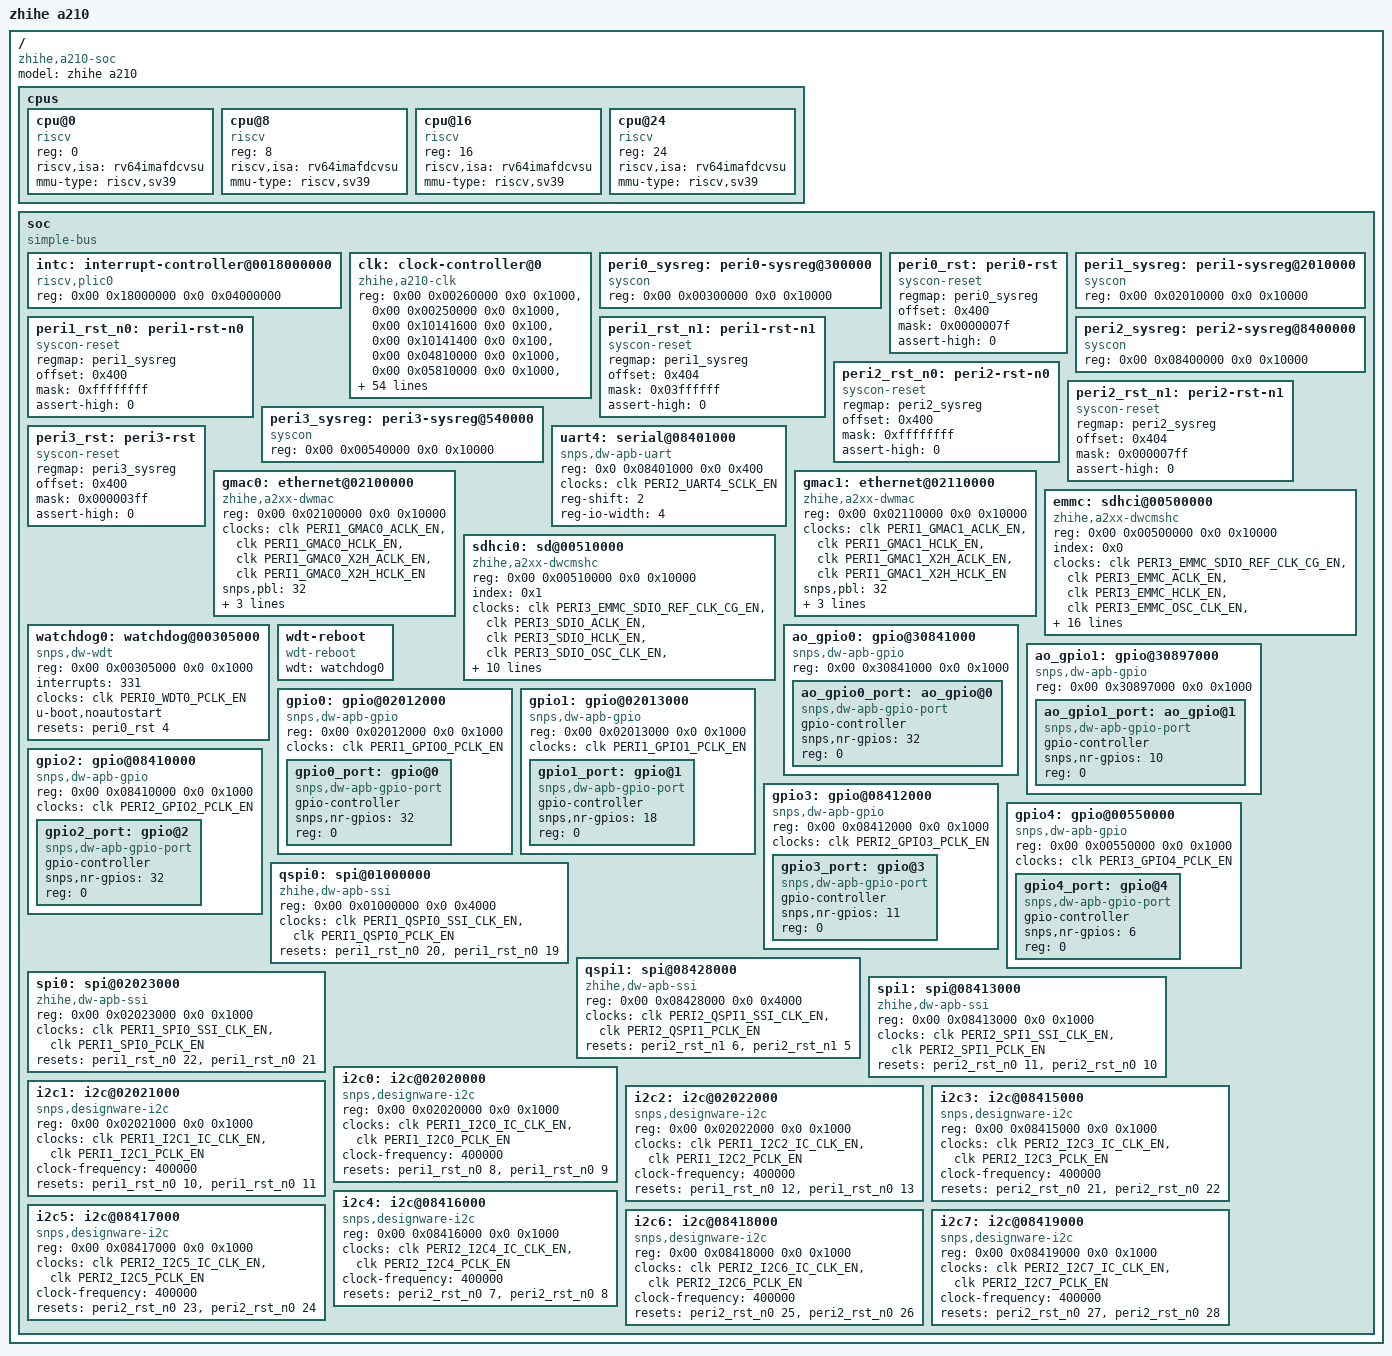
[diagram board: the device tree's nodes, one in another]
// SPDX-License-Identifier: GPL-2.0+
/*
 * (C) Copyright 2024 Zhihe Computing Technology (Shenzhen) Co., Ltd.
 */

#include <dt-bindings/clock/a210-clock.h>

/ {
	model = "zhihe a210";
	compatible = "zhihe,a210-soc";
	#address-cells = <2>;
	#size-cells = <2>;

	cpus {
		#address-cells = <1>;
		#size-cells = <0>;
		bootph-pre-ram;
		cpu@0 {
			device_type = "cpu";
			reg = <0>;
			status = "okay";
			compatible = "riscv";
			riscv,isa = "rv64imafdcvsu";
			mmu-type = "riscv,sv39";
			bootph-pre-ram;
		};

		cpu@8 {
			device_type = "cpu";
			reg = <8>;
			status = "okay";
			compatible = "riscv";
			riscv,isa = "rv64imafdcvsu";
			mmu-type = "riscv,sv39";
			bootph-pre-ram;
		};
		cpu@16 {
			device_type = "cpu";
			reg = <16>;
			status = "okay";
			compatible = "riscv";
			riscv,isa = "rv64imafdcvsu";
			mmu-type = "riscv,sv39";
			bootph-pre-ram;
		};
		cpu@24 {
			device_type = "cpu";
			reg = <24>;
			status = "okay";
			compatible = "riscv";
			riscv,isa = "rv64imafdcvsu";
			mmu-type = "riscv,sv39";
			bootph-pre-ram;
		};
	};

	soc {
		#address-cells = <2>;
		#size-cells = <2>;
		compatible = "simple-bus";
		ranges;
		bootph-pre-ram;

		intc: interrupt-controller@0018000000 {
			compatible = "riscv,plic0";
			reg = <0x00 0x18000000 0x0 0x04000000>;
			status = "okay";
		};

		clk: clock-controller@0 {
			compatible = "zhihe,a210-clk";
			reg = <0x00 0x00260000 0x0 0x1000>,<0x00 0x00250000 0x0 0x1000>,
				  <0x00 0x10141600 0x0 0x100>,<0x00 0x10141400 0x0 0x100>,
				  <0x00 0x04810000 0x0 0x1000>,<0x00 0x05810000 0x0 0x1000>,
				  <0x00 0x04900000 0x0 0x1000>,<0x00 0x20250000 0x0 0x1000>,
				  <0x00 0x10140a00 0x0 0x100>, <0x00 0x10140c00 0x0 0x100>,
				  <0x00 0x00300000 0x0 0x1000>,<0x00 0x02010000 0x0 0x1000>,
				  <0x00 0x08400000 0x0 0x1000>,<0x00 0x00540000 0x0 0x1000>;
			reg-names = "PLL_WRAP","TOP_CRG","CPU_SS_CLK_SYSREG","CPU_SS_CPU_PLL",
						"DDR0_SYSREG","DDR1_SYSREG","SLC_DUAL_SYSREG","TOP_CRG_T",
						"CPU_SS_C908_CPU_CLK_CCU","CPU_SS_C920_CPU_CLK_CCU",
						"PERI0_SYSREG", "PERI1_SYSREG", "PERI2_SYSREG", "PERI3_SYSREG";
			assigned-clocks = <&clk TOP_CFG_ACLK_DIV>, <&clk TOP_PCLK_DIV>,
							<&clk AMUX_CLK_DIV>, <&clk IOMMU_PTW_ACLK_DIV>,
							<&clk NOC_CCLK_MUX>, <&clk NOC_CCLK_DIV>,
							<&clk TOP_CPUSYS_BUS_CLK_MUX>, <&clk TOP_CPUSYS_BUS_CLK_DIV>,
							<&clk TOP_CPUSYS_PIC_CLK_MUX>, <&clk TOP_CPUSYS_PIC_CLK_DIV>,
							<&clk TOP_PERI_EMMC_REF_CLK_MUX>, <&clk TOP_PERI_EMMC_REF_CLK_DIV>,
							<&clk TOP_PERI_MST_ACLK0_DIV>, <&clk TOP_PERI_MST_CLK1_DIV>,
							<&clk TOP_PERI_HIRES_CLK0_DIV>, <&clk TOP_PERI_HIRES_CLK1_DIV>,
							<&clk TOP_PERI_SPI_SSI_CLK0_DIV>, <&clk TOP_PERI_SPI_SSI_CLK1_DIV>,
							<&clk TOP_PERI_QSPI_SSI_CLK_MUX0>, <&clk TOP_PERI_QSPI_SSI_CLK_MUX1>,
							<&clk I2C_IC_CLK>, <&clk TOP_UART_SCLK_MUX>;
			assigned-clock-rates = <330000000>, /* top_cfg_aclk */
							<165000000>, /* top_pclk */
							<660000000>, /* top_amux_clk_div */
							<330000000>, /* iommu_ptw_aclk_div */
							<0>,         /* noc_cclk_mux */
							<880000000>, /* noc_cclk_div */
							<0>,         /* top_cpusys_bus_clk_mux */
							<1000000000>,/* top_cpusys_bus_clk */
							<0>,         /* top_cpusys_pic_clk_mux */
							<1000000000>,/* top_cpusys_pic_clk */
							<0>,         /* emmc_ref_clk_mux */
							<786432000>, /* emmc_ref_clk */
							<330000000>, /* peri1_mst_aclk */
							<440000000>, /* peri3_mst_aclk */
							<80000000>,  /* peri1_hires_clk */
							<80000000>,  /* peri2_hires_clk */
							<421478400>, /* peri1_spi_ssi_clk */
							<421478400>, /* peri2_spi_ssi_clk */
							<421478400>, /* peri1_qspi_ssi_clk */
							<421478400>, /* peri2_qspi_ssi_clk */
							<100000000>, /* i2c_ic_clk */
							<100000000>;  /* uart_sclk */
			assigned-clock-parents = <&clk VIDEO_PLL_FOUT1PH0>, <0>,
							<0>, <0>,
							<&clk VIDEO_PLL_FOUTVCO>, <0>,
							<&clk VIDEO_PLL_FOUTVCO>, <0>,
							<&clk GMAC_PLL_FOUTVCO>, <0>,
							<&clk AUDIO0_PLL_FOUTVCO>, <&clk TOP_PERI_EMMC_REF_CLK_MUX>,
							<&clk VIDEO_PLL_FOUT1PH0>, <0>,
							<0>, <0>,
							<&clk AUDIO1_PLL_FOUTVCO>, <&clk AUDIO1_PLL_FOUTVCO>,
							<&clk TOP_PERI_QSPI0_SSI_CLK_DIV1>, <&clk TOP_PERI_QSPI1_SSI_CLK_DIV1>,
							<&clk GMAC_PLL_FOUTPOSTDIV>, <&clk UART_SCLK_100M>;
			#clock-cells = <1>;
			bootph-pre-ram;
			/* pll */
			audio0_pll_foutvco_frequency = <2359296000>;
			audio1_pll_foutvco_frequency = <2528870400>;
			video_pll_foutvco_frequency = <2640000000>;
			gmac_pll_foutvco_frequency = <3000000000>;
			dpu1_pll_foutvco_frequency = <2376000000>;
			dpu2_pll_foutvco_frequency = <2376000000>;
			c908_pll_foutvco_frequency = <1200000000>;
			c920_pll_foutvco_frequency = <2040000000>;

			status = "okay";
		};

		peri0_sysreg: peri0-sysreg@300000 {
			compatible = "syscon";
			reg = <0x00 0x00300000 0x0 0x10000>;
		};

		peri0_rst: peri0-rst {
			compatible = "syscon-reset";
			regmap = <&peri0_sysreg>;
			offset = <0x400>;
			mask = <0x0000007f>;
			assert-high = <0>;
			#reset-cells = <1>;
		};
	
		peri1_sysreg: peri1-sysreg@2010000 {
			compatible = "syscon";
			reg = <0x00 0x02010000 0x0 0x10000>;
		};

		peri1_rst_n0: peri1-rst-n0 {
			compatible = "syscon-reset";
			regmap = <&peri1_sysreg>;
			offset = <0x400>;
			mask = <0xffffffff>;
			assert-high = <0>;
			#reset-cells = <1>;
		};

		peri1_rst_n1: peri1-rst-n1 {
			compatible = "syscon-reset";
			regmap = <&peri1_sysreg>;
			offset = <0x404>;
			mask = <0x03ffffff>;
			assert-high = <0>;
			#reset-cells = <1>;
		};

		peri2_sysreg: peri2-sysreg@8400000 {
			compatible = "syscon";
			reg = <0x00 0x08400000 0x0 0x10000>;
		};

		peri2_rst_n0: peri2-rst-n0 {
			compatible = "syscon-reset";
			regmap = <&peri2_sysreg>;
			offset = <0x400>;
			mask = <0xffffffff>;
			assert-high = <0>;
			#reset-cells = <1>;
		};

		peri2_rst_n1: peri2-rst-n1 {
			compatible = "syscon-reset";
			regmap = <&peri2_sysreg>;
			offset = <0x404>;
			mask = <0x000007ff>;
			assert-high = <0>;
			#reset-cells = <1>;
		};

		peri3_sysreg: peri3-sysreg@540000 {
			compatible = "syscon";
			reg = <0x00 0x00540000 0x0 0x10000>;
		};

		peri3_rst: peri3-rst {
			compatible = "syscon-reset";
			regmap = <&peri3_sysreg>;
			offset = <0x400>;
			mask = <0x000003ff>;
			assert-high = <0>;
			#reset-cells = <1>;
		};

		uart4: serial@08401000 {
			compatible = "snps,dw-apb-uart";
			reg = <0x0 0x08401000 0x0 0x400>;
			clocks = <&clk PERI2_UART4_SCLK_EN>;
			reg-shift = <2>;
			reg-io-width = <4>;
			bootph-pre-ram;
		};

		gmac0: ethernet@02100000{
			compatible = "zhihe,a2xx-dwmac";
			reg = <0x00 0x02100000 0x0 0x10000>;
			clocks = <&clk PERI1_GMAC0_ACLK_EN>, <&clk PERI1_GMAC0_HCLK_EN>, <&clk PERI1_GMAC0_X2H_ACLK_EN>, <&clk PERI1_GMAC0_X2H_HCLK_EN>;
			clock-names = "aclk", "hclk", "x2h_aclk", "x2h_hclk";
			snps,pbl = <32>;
			snps,fixed-burst;
			resets = <&peri1_rst_n0 0>, <&peri1_rst_n0 1>, <&peri1_rst_n0 31>, <&peri1_rst_n1 0>;
			reset-names = "arst", "hrst", "x2h_arst", "x2h_hrst";
			status = "okay";
		};

		gmac1: ethernet@02110000{
			compatible = "zhihe,a2xx-dwmac";
			reg = <0x00 0x02110000 0x0 0x10000>;
			clocks = <&clk PERI1_GMAC1_ACLK_EN>, <&clk PERI1_GMAC1_HCLK_EN>, <&clk PERI1_GMAC1_X2H_ACLK_EN>, <&clk PERI1_GMAC1_X2H_HCLK_EN>;
			clock-names = "aclk", "hclk", "x2h_aclk", "x2h_hclk";
			snps,pbl = <32>;
			snps,fixed-burst;
			resets = <&peri1_rst_n0 2>, <&peri1_rst_n0 3>, <&peri1_rst_n1 1>, <&peri1_rst_n1 2>;
			reset-names = "arst", "hrst", "x2h_arst", "x2h_hrst";
			status = "okay";
		};

		emmc: sdhci@00500000 {
			compatible = "zhihe,a2xx-dwcmshc";
			reg = <0x00 0x00500000 0x0 0x10000>;
			index = <0x0>;
			clocks = <&clk PERI3_EMMC_SDIO_REF_CLK_CG_EN>,
					<&clk PERI3_EMMC_ACLK_EN>,
					<&clk PERI3_EMMC_HCLK_EN>,
					<&clk PERI3_EMMC_OSC_CLK_EN>,
					<&clk PERI3_EMMC_X2X_ACLK_M_EN>,
					<&clk PERI3_EMMC_X2X_ACLK_S_EN>;
			clock-names = "core", "aclk", "hclk", "oscclk", "aclkm", "aclks";
			resets = <&peri3_rst 3>, <&peri3_rst 4>, <&peri3_rst 5>;
			reset-names = "rst_n", "x2x_arst_n_m", "x2x_arst_n_s";
			sdhci-caps-mask = <0x0 0x1000000>;
			mmc-hs400-enhanced-strobe;
			mmc-hs400-1_8v;
			mmc-hs200-1_8v;
			//mmc-ddr-1_8v;
			cap-mmc-highspeed;
			non-removable;
			no-sdio;
			no-sd;
			bus-width = <8>;
			pull_up;
			io_fixed_1v8;
			fifo-mode;
			broken-cd;
			bootph-pre-ram;
			status = "okay";
		};

		sdhci0: sd@00510000 {
			compatible = "zhihe,a2xx-dwcmshc";
			reg = <0x00 0x00510000 0x0 0x10000>;
			index = <0x1>;
			clocks = <&clk PERI3_EMMC_SDIO_REF_CLK_CG_EN>,
					<&clk PERI3_SDIO_ACLK_EN>,
					<&clk PERI3_SDIO_HCLK_EN>,
					<&clk PERI3_SDIO_OSC_CLK_EN>,
					<&clk PERI3_SDIO_X2X_ACLK_M_EN>,
					<&clk PERI3_SDIO_X2X_ACLK_S_EN>;
			clock-names = "core", "aclk", "hclk", "oscclk", "aclkm", "aclks";
			resets = <&peri3_rst 6>, <&peri3_rst 7>, <&peri3_rst 8>;
			reset-names = "rst_n", "x2x_arst_n_m", "x2x_arst_n_s";
			sd-uhs-sdr104;
			//sd-uhs-ddr50;
			sd-uhs-sdr50;
			sd-uhs-sdr25;
			sd-uhs-sdr12;
			cap-sd-highspeed;
			pull_up;
			bus-width = <4>;
			status = "okay";
		};

		watchdog0: watchdog@00305000 {
			compatible = "snps,dw-wdt";
			reg = <0x00 0x00305000 0x0 0x1000>;
			interrupts = <331>;
			clocks = <&clk PERI0_WDT0_PCLK_EN>;
			u-boot,noautostart;
			resets = <&peri0_rst 4>;
			reset-names = "prst";
			status = "okay";
		};

		wdt-reboot {
			compatible = "wdt-reboot";
			wdt = <&watchdog0>;
		};

		ao_gpio0: gpio@30841000 {
			compatible = "snps,dw-apb-gpio";
			#address-cells = <1>;
			#size-cells = <0>;
			reg = <0x00 0x30841000 0x0 0x1000>;

			ao_gpio0_port: ao_gpio@0 {
				compatible = "snps,dw-apb-gpio-port";
				gpio-controller;
				#gpio-cells = <2>;
				snps,nr-gpios = <32>;
				reg = <0>;
			};
		};

		ao_gpio1: gpio@30897000 {
			compatible = "snps,dw-apb-gpio";
			#address-cells = <1>;
			#size-cells = <0>;
			reg = <0x00 0x30897000 0x0 0x1000>;

			ao_gpio1_port: ao_gpio@1 {
				compatible = "snps,dw-apb-gpio-port";
				gpio-controller;
				#gpio-cells = <2>;
				snps,nr-gpios = <10>;
				reg = <0>;
			};
		};

		gpio0: gpio@02012000 {
			compatible = "snps,dw-apb-gpio";
			#address-cells = <1>;
			#size-cells = <0>;
			reg = <0x00 0x02012000 0x0 0x1000>;
			clocks = <&clk PERI1_GPIO0_PCLK_EN>;

			gpio0_port: gpio@0 {
				compatible = "snps,dw-apb-gpio-port";
				gpio-controller;
				#gpio-cells = <2>;
				snps,nr-gpios = <32>;
				reg = <0>;
			};
		};

		gpio1: gpio@02013000 {
			compatible = "snps,dw-apb-gpio";
			#address-cells = <1>;
			#size-cells = <0>;
			reg = <0x00 0x02013000 0x0 0x1000>;
			clocks = <&clk PERI1_GPIO1_PCLK_EN>;

			gpio1_port: gpio@1 {
				compatible = "snps,dw-apb-gpio-port";
				gpio-controller;
				#gpio-cells = <2>;
				snps,nr-gpios = <18>;
				reg = <0>;
			};
		};

		gpio2: gpio@08410000 {
			compatible = "snps,dw-apb-gpio";
			#address-cells = <1>;
			#size-cells = <0>;
			reg = <0x00 0x08410000 0x0 0x1000>;
			clocks = <&clk PERI2_GPIO2_PCLK_EN>;

			gpio2_port: gpio@2 {
				compatible = "snps,dw-apb-gpio-port";
				gpio-controller;
				#gpio-cells = <2>;
				snps,nr-gpios = <32>;
				reg = <0>;
			};
		};

		gpio3: gpio@08412000 {
			compatible = "snps,dw-apb-gpio";
			#address-cells = <1>;
			#size-cells = <0>;
			reg = <0x00 0x08412000 0x0 0x1000>;
			clocks = <&clk PERI2_GPIO3_PCLK_EN>;

			gpio3_port: gpio@3 {
				compatible = "snps,dw-apb-gpio-port";
				gpio-controller;
				#gpio-cells = <2>;
				snps,nr-gpios = <11>;
				reg = <0>;
			};
		};

		gpio4: gpio@00550000 {
			compatible = "snps,dw-apb-gpio";
			#address-cells = <1>;
			#size-cells = <0>;
			reg = <0x00 0x00550000 0x0 0x1000>;
			clocks = <&clk PERI3_GPIO4_PCLK_EN>;

			gpio4_port: gpio@4 {
				compatible = "snps,dw-apb-gpio-port";
				gpio-controller;
				#gpio-cells = <2>;
				snps,nr-gpios = <6>;
				reg = <0>;
			};
		};

		qspi0: spi@01000000 {
			compatible = "zhihe,dw-apb-ssi";
			#address-cells = <1>;
			#size-cells =<0>;
			reg = <0x00 0x01000000 0x0 0x4000>;
			clocks = <&clk PERI1_QSPI0_SSI_CLK_EN>, <&clk PERI1_QSPI0_PCLK_EN>;
			clock-names = "sclk", "pclk";
			resets = <&peri1_rst_n0 20>, <&peri1_rst_n0 19>;
			reset-names = "srst", "prst";
		};

		qspi1: spi@08428000 {
			compatible = "zhihe,dw-apb-ssi";
			#address-cells = <1>;
			#size-cells =<0>;
			reg = <0x00 0x08428000 0x0 0x4000>;
			clocks = <&clk PERI2_QSPI1_SSI_CLK_EN>, <&clk PERI2_QSPI1_PCLK_EN>;
			clock-names = "sclk", "pclk";
			resets = <&peri2_rst_n1 6>, <&peri2_rst_n1 5>;
			reset-names = "srst", "prst";
		};

		spi0: spi@02023000 {
			compatible = "zhihe,dw-apb-ssi";
			#address-cells = <1>;
			#size-cells = <0>;
			reg = <0x00 0x02023000 0x0 0x1000>;
			clocks = <&clk PERI1_SPI0_SSI_CLK_EN>, <&clk PERI1_SPI0_PCLK_EN>;
			clock-names = "sclk", "pclk";
			resets = <&peri1_rst_n0 22>, <&peri1_rst_n0 21>;
			reset-names = "srst", "prst";
		};

		spi1: spi@08413000 {
			compatible = "zhihe,dw-apb-ssi";
			#address-cells = <1>;
			#size-cells = <0>;
			reg = <0x00 0x08413000 0x0 0x1000>;
			clocks = <&clk PERI2_SPI1_SSI_CLK_EN>, <&clk PERI2_SPI1_PCLK_EN>;
			clock-names = "sclk", "pclk";
			resets = <&peri2_rst_n0 11>, <&peri2_rst_n0 10>;
			reset-names = "srst", "prst";
		};

		i2c0: i2c@02020000 {
			compatible = "snps,designware-i2c";
			reg = <0x00 0x02020000 0x0 0x1000>;
			clocks = <&clk PERI1_I2C0_IC_CLK_EN>, <&clk PERI1_I2C0_PCLK_EN>;
			clock-names = "clk", "pclk";
			clock-frequency = <400000>;
			#address-cells = <1>;
			#size-cells = <0>;
			resets = <&peri1_rst_n0 8>, <&peri1_rst_n0 9>;
			reset-names = "rst", "prst";
		};

		i2c1: i2c@02021000{
			compatible = "snps,designware-i2c";
			reg = <0x00 0x02021000 0x0 0x1000>;
			clocks = <&clk PERI1_I2C1_IC_CLK_EN>, <&clk PERI1_I2C1_PCLK_EN>;
			clock-names = "clk", "pclk";
			clock-frequency = <400000>;
			#address-cells = <1>;
			#size-cells = <0>;
			resets = <&peri1_rst_n0 10>, <&peri1_rst_n0 11>;
			reset-names = "rst", "prst";
		};

		i2c2: i2c@02022000{
			compatible = "snps,designware-i2c";
			reg = <0x00 0x02022000 0x0 0x1000>;
			clocks = <&clk PERI1_I2C2_IC_CLK_EN>, <&clk PERI1_I2C2_PCLK_EN>;
			clock-names = "clk", "pclk";
			clock-frequency = <400000>;
			#address-cells = <1>;
			#size-cells = <0>;
			resets = <&peri1_rst_n0 12>, <&peri1_rst_n0 13>;
			reset-names = "rst", "prst";
		};

		i2c3: i2c@08415000{
			compatible = "snps,designware-i2c";
			reg = <0x00 0x08415000 0x0 0x1000>;
			clocks = <&clk PERI2_I2C3_IC_CLK_EN>, <&clk PERI2_I2C3_PCLK_EN>;
			clock-names = "clk", "pclk";
			clock-frequency = <400000>;
			#address-cells = <1>;
			#size-cells = <0>;
			resets = <&peri2_rst_n0 21>, <&peri2_rst_n0 22>;
			reset-names = "rst", "prst";
		};

		i2c4: i2c@08416000{
			compatible = "snps,designware-i2c";
			reg = <0x00 0x08416000 0x0 0x1000>;
			clocks = <&clk PERI2_I2C4_IC_CLK_EN>, <&clk PERI2_I2C4_PCLK_EN>;
			clock-names = "clk", "pclk";
			clock-frequency = <400000>;
			#address-cells = <1>;
			#size-cells = <0>;
			resets = <&peri2_rst_n0 7>, <&peri2_rst_n0 8>;
			reset-names = "rst", "prst";
		};

		i2c5: i2c@08417000{
			compatible = "snps,designware-i2c";
			reg = <0x00 0x08417000 0x0 0x1000>;
			clocks = <&clk PERI2_I2C5_IC_CLK_EN>, <&clk PERI2_I2C5_PCLK_EN>;
			clock-names = "clk", "pclk";
			clock-frequency = <400000>;
			#address-cells = <1>;
			#size-cells = <0>;
			resets = <&peri2_rst_n0 23>, <&peri2_rst_n0 24>;
			reset-names = "rst", "prst";
		};

		i2c6: i2c@08418000{
			compatible = "snps,designware-i2c";
			reg = <0x00 0x08418000 0x0 0x1000>;
			clocks = <&clk PERI2_I2C6_IC_CLK_EN>, <&clk PERI2_I2C6_PCLK_EN>;
			clock-names = "clk", "pclk";
			clock-frequency = <400000>;
			#address-cells = <1>;
			#size-cells = <0>;
			resets = <&peri2_rst_n0 25>, <&peri2_rst_n0 26>;
			reset-names = "rst", "prst";
		};

		i2c7: i2c@08419000{
			compatible = "snps,designware-i2c";
			reg = <0x00 0x08419000 0x0 0x1000>;
			clocks = <&clk PERI2_I2C7_IC_CLK_EN>, <&clk PERI2_I2C7_PCLK_EN>;
			clock-names = "clk", "pclk";
			clock-frequency = <400000>;
			#address-cells = <1>;
			#size-cells = <0>;
			resets = <&peri2_rst_n0 27>, <&peri2_rst_n0 28>;
			reset-names = "rst", "prst";
		};
	};
};
